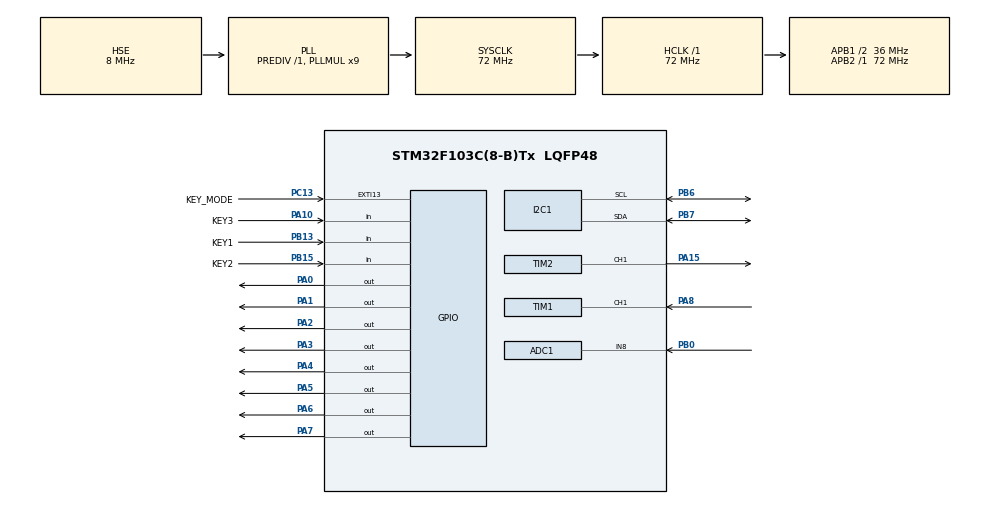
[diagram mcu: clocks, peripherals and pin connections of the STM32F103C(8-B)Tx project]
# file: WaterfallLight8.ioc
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ADC1.Channel-0\#ChannelRegularConversion=ADC_CHANNEL_8
ADC1.ContinuousConvMode=ENABLE
ADC1.NbrOfConversionFlag=1
ADC1.Rank-0\#ChannelRegularConversion=1
ADC1.SamplingTime-0\#ChannelRegularConversion=ADC_SAMPLETIME_1CYCLE_5
ADC1.master=1
Mcu.Family=STM32F1
Mcu.Name=STM32F103C(8-B)Tx
Mcu.Package=LQFP48
NVIC.EXTI15_10_IRQn=true\:0\:0\:false\:false\:true\:true\:true\:true
NVIC.I2C1_ER_IRQn=true\:0\:0\:false\:false\:true\:true\:true\:true
NVIC.I2C1_EV_IRQn=true\:0\:0\:false\:false\:true\:true\:true\:true
NVIC.PriorityGroup=NVIC_PRIORITYGROUP_4
NVIC.TIM1_CC_IRQn=true\:0\:0\:false\:false\:true\:true\:true\:true
NVIC.TIM2_IRQn=true\:0\:0\:false\:false\:true\:true\:true\:true
PA0-WKUP.GPIO_PuPd=GPIO_PULLUP
PA0-WKUP.Signal=GPIO_Output
PA1.Signal=GPIO_Output
PA10.GPIO_Label=KEY3
PA10.GPIO_PuPd=GPIO_PULLUP
PA10.Signal=GPIO_Input
PA13.Mode=Serial_Wire
PA13.Signal=SYS_JTMS-SWDIO
PA14.Mode=Serial_Wire
PA14.Signal=SYS_JTCK-SWCLK
PA15.Signal=S_TIM2_CH1_ETR
PA2.GPIO_PuPd=GPIO_PULLUP
PA2.Signal=GPIO_Output
PA3.GPIO_PuPd=GPIO_PULLUP
PA3.Signal=GPIO_Output
PA4.GPIO_PuPd=GPIO_PULLUP
PA4.Signal=GPIO_Output
PA5.GPIO_PuPd=GPIO_PULLUP
PA5.Signal=GPIO_Output
PA6.GPIO_PuPd=GPIO_PULLUP
PA6.Signal=GPIO_Output
PA7.GPIO_PuPd=GPIO_PULLUP
PA7.Signal=GPIO_Output
PA8.Signal=S_TIM1_CH1
PB0.Signal=ADCx_IN8
PB13.GPIO_Label=KEY1
PB13.GPIO_PuPd=GPIO_PULLUP
PB13.Signal=GPIO_Input
PB15.GPIO_Label=KEY2
PB15.GPIO_PuPd=GPIO_PULLUP
PB15.Signal=GPIO_Input
PB6.Mode=I2C
PB6.Signal=I2C1_SCL
PB7.Mode=I2C
PB7.Signal=I2C1_SDA
PC13-TAMPER-RTC.GPIO_Label=KEY_MODE
PC13-TAMPER-RTC.GPIO_PuPd=GPIO_PULLUP
PC13-TAMPER-RTC.Signal=GPXTI13
PC14-OSC32_IN.Mode=LSE-External-Oscillator
PC14-OSC32_IN.Signal=RCC_OSC32_IN
PC15-OSC32_OUT.Mode=LSE-External-Oscillator
PC15-OSC32_OUT.Signal=RCC_OSC32_OUT
PD0-OSC_IN.Mode=HSE-External-Oscillator
PD0-OSC_IN.Signal=RCC_OSC_IN
PD1-OSC_OUT.Mode=HSE-External-Oscillator
PD1-OSC_OUT.Signal=RCC_OSC_OUT
ProjectManager.HeapSize=0x200
ProjectManager.StackSize=0x400
ProjectManager.TargetToolchain=MDK-ARM V5.32
RCC.ADCPresc=RCC_ADCPCLK2_DIV6
RCC.AHBFreq_Value=72000000
RCC.APB1CLKDivider=RCC_HCLK_DIV2
RCC.APB1Freq_Value=36000000
RCC.APB1TimFreq_Value=72000000
RCC.APB2Freq_Value=72000000
RCC.APB2TimFreq_Value=72000000
RCC.HCLKFreq_Value=72000000
RCC.PLLMUL=RCC_PLL_MUL9
RCC.PLLSourceVirtual=RCC_PLLSOURCE_HSE
RCC.SYSCLKFreq_VALUE=72000000
RCC.SYSCLKSource=RCC_SYSCLKSOURCE_PLLCLK
RCC.USBFreq_Value=72000000
SH.ADCx_IN8.0=ADC1_IN8,IN8
SH.S_TIM1_CH1.0=TIM1_CH1,TriggerSource_TI1FP1
SH.S_TIM1_CH1.1=TIM1_CH1,Input_Capture1_from_TI1
SH.S_TIM2_CH1_ETR.0=TIM2_CH1,PWM Generation1 CH1
TIM1.Channel-Input_Capture1_from_TI1=TIM_CHANNEL_1
TIM1.Channel-Input_Capture2_from_TI1_63=TIM_CHANNEL_2
TIM2.Channel-PWM\ Generation1\ CH1=TIM_CHANNEL_1
TIM2.Period=20000-1
TIM2.Prescaler=7199
TIM2.Pulse-PWM\ Generation1\ CH1=10000
VP_TIM1_VS_ControllerModeReset.Mode=Reset Mode
VP_TIM1_VS_indirect_ch1.Mode=Input_Capture2_from_TI1_63
board=custom

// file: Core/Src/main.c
/* USER CODE BEGIN Header */
/**
  ******************************************************************************
  * @file           : main.c
  * @brief          : Main program body
  ******************************************************************************
  * @attention
  *
  * Copyright (c) 2026 STMicroelectronics.
  * All rights reserved.
  *
  * This software is licensed under terms that can be found in the LICENSE file
  * in the root directory of this software component.
  * If no LICENSE file comes with this software, it is provided AS-IS.
  *
  ******************************************************************************
  */
/* USER CODE END Header */
#include "main.h"
#include "adc.h"
#include "i2c.h"
#include "tim.h"
#include "gpio.h"

/* USER CODE BEGIN Includes */
#include "tim2_pwm.h"
#include "adc_pot.h"
/* USER CODE END Includes */

void SystemClock_Config(void);

int main(void)
{

  /* MCU Configuration--------------------------------------------------------*/

  /* Reset of all peripherals, Initializes the Flash interface and the Systick. */
  HAL_Init();

  /* Configure the system clock */
  SystemClock_Config();

  /* Initialize all configured peripherals */
  MX_GPIO_Init();
  MX_ADC1_Init();
  MX_I2C1_Init();
  MX_TIM1_Init();
  MX_TIM2_Init();
  /* USER CODE BEGIN 2 */
  PWM_TIM2_Init();
  PWM_TIM2_Start();
  ADC_Pot_Init();
  /* USER CODE END 2 */

  /* Infinite loop */
  while (1)
  {
    PWM_TIM2_Setfreq(50);
    PWM_TIM2_Setduty(40);
  }
}

void SystemClock_Config(void)
{
  RCC_OscInitTypeDef RCC_OscInitStruct = {0};
  RCC_ClkInitTypeDef RCC_ClkInitStruct = {0};
  RCC_PeriphCLKInitTypeDef PeriphClkInit = {0};

  /** Initializes the RCC Oscillators according to the specified parameters
  * in the RCC_OscInitTypeDef structure.
  */
  RCC_OscInitStruct.OscillatorType = RCC_OSCILLATORTYPE_HSE;
  RCC_OscInitStruct.HSEState = RCC_HSE_ON;
  RCC_OscInitStruct.HSEPredivValue = RCC_HSE_PREDIV_DIV1;
  RCC_OscInitStruct.HSIState = RCC_HSI_ON;
  RCC_OscInitStruct.PLL.PLLState = RCC_PLL_ON;
  RCC_OscInitStruct.PLL.PLLSource = RCC_PLLSOURCE_HSE;
  RCC_OscInitStruct.PLL.PLLMUL = RCC_PLL_MUL9;
  if (HAL_RCC_OscConfig(&RCC_OscInitStruct) != HAL_OK)
  {
    Error_Handler();
  }

  /** Initializes the CPU, AHB and APB buses clocks
  */
  RCC_ClkInitStruct.ClockType = RCC_CLOCKTYPE_HCLK|RCC_CLOCKTYPE_SYSCLK
                              |RCC_CLOCKTYPE_PCLK1|RCC_CLOCKTYPE_PCLK2;
  RCC_ClkInitStruct.SYSCLKSource = RCC_SYSCLKSOURCE_PLLCLK;
  RCC_ClkInitStruct.AHBCLKDivider = RCC_SYSCLK_DIV1;
  RCC_ClkInitStruct.APB1CLKDivider = RCC_HCLK_DIV2;
  RCC_ClkInitStruct.APB2CLKDivider = RCC_HCLK_DIV1;

  if (HAL_RCC_ClockConfig(&RCC_ClkInitStruct, FLASH_LATENCY_2) != HAL_OK)
  {
    Error_Handler();
  }
  PeriphClkInit.PeriphClockSelection = RCC_PERIPHCLK_ADC;
  PeriphClkInit.AdcClockSelection = RCC_ADCPCLK2_DIV6;
  if (HAL_RCCEx_PeriphCLKConfig(&PeriphClkInit) != HAL_OK)
  {
    Error_Handler();
  }
}

void Error_Handler(void)
{
  __disable_irq();
  while (1)
  {
  }
}
